# GD32W515Px register map
File version: 1.0
CPU: CM33 r0p0, little endian, MPU, FPU, 4 interrupt priority bits
Registers are 32-bit, read-write, reset 0x0 unless marked. A register's access mark holds for its fields unless they carry their own. Offsets are from the block's base; [hi:lo] are bit positions; {n}, {i} and the like mark numbered series.

## SYSCFG — System configuration controller
Base 0x40013800
Same registers: SEC_SYSCFG 0x50013800
0x00 CFG0 — Configuration register 0
  [1:0] BOOT_MODE
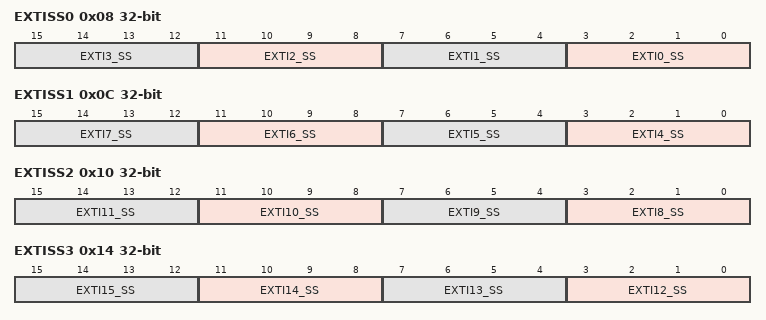
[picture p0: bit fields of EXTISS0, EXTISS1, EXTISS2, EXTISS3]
0x08 EXTISS0 — EXTI sources selection register 0
  [4n+3:4n] EXTI{n}_SS (n=0..3) — EXTI {n} sources selection
0x0C EXTISS1 — EXTI sources selection register 1
  [4n-13:4n-16] EXTI{n}_SS (n=4..7) — EXTI {n} sources selection
0x10 EXTISS2 — EXTI sources selection register 2
  [4n-29:4n-32] EXTI{n}_SS (n=8..11) — EXTI {n} sources selection
0x14 EXTISS3 — EXTI sources selection register 3
  [4n-45:4n-48] EXTI{n}_SS (n=12..15) — EXTI {n} sources selection
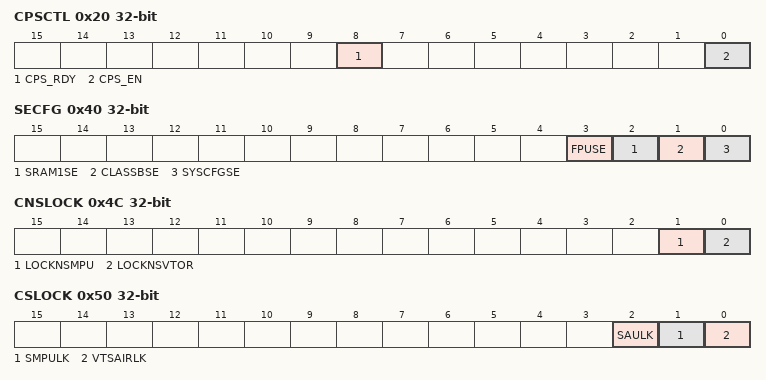
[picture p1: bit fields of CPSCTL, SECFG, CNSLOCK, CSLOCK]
0x20 CPSCTL access per field — I/O compensation control register
  [8] CPS_RDY ro — I/O compensation cell is ready or not
  [0] CPS_EN rw — I/O compensation cell enable
0x40 SECFG — SYSCFG secure configuration register
  [3] FPUSE — FPU security
  [2] SRAM1SE — SRAM1 security
  [1] CLASSBSE — ClassB security
  [0] SYSCFGSE — SYSCFG clock control security
0x48 FPUINTMSK reset 0x1F — FPU interrupt mask register
  [5:0] FPU_IE — Floating point unit interrupts enable bits
0x4C CNSLOCK — SYSCFG CPU non-secure lock register
  [1] LOCKNSMPU — Non-secure MPU registers lock
  [0] LOCKNSVTOR — VTOR_NS register lock
0x50 CSLOCK — SYSCFG CPU secure lock register
  [2] SAULK — SAU registers lock
  [1] SMPULK — Secure MPU registers lock
  [0] VTSAIRLK — VTOR_S register and AIRCR register bits lock
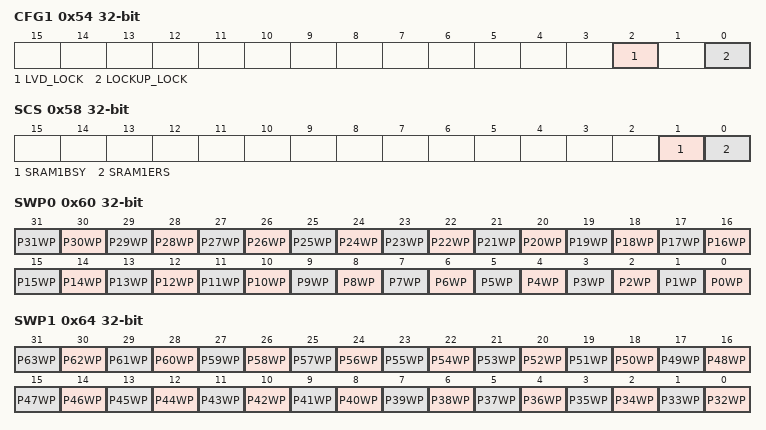
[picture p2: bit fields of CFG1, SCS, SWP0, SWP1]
0x54 CFG1 — SYSCFG configuration register 1
  [2] LVD_LOCK — LVD lock enable bit
  [0] LOCKUP_LOCK — Cortex M33 LOCKUP (hardfault) output enable bit
0x58 SCS access per field — SYSCFG SRAM1 control and status register
  [1] SRAM1BSY ro — SRAM1 busy by erase operation
  [0] SRAM1ERS rw — SRAM1 erase
0x5C SKEY wo — SYSCFG SRAM1 key register
  [7:0] KEY — SRAM1 write protection key for software erase
0x60 SWP0 — SYSCFG SRAM1 write protection register 0
  [n] P{n}WP (n=0..31) — SRAM1 1 Kbyte page {n} write protection
0x64 SWP1 — SYSCFG SRAM1 write protection register 1
  [n-32] P{n}WP (n=32..63) — SRAM1 1 Kbyte page {n} write protection
0x6C RSSCMD — SYSCFG RSS command register
  [7:0] RSSCMD — RSS commands

## TZBMPC0 — Memory protection controller - block based
Base 0x400A0800
Same registers: SEC_TZBMPC0 0x500A0800
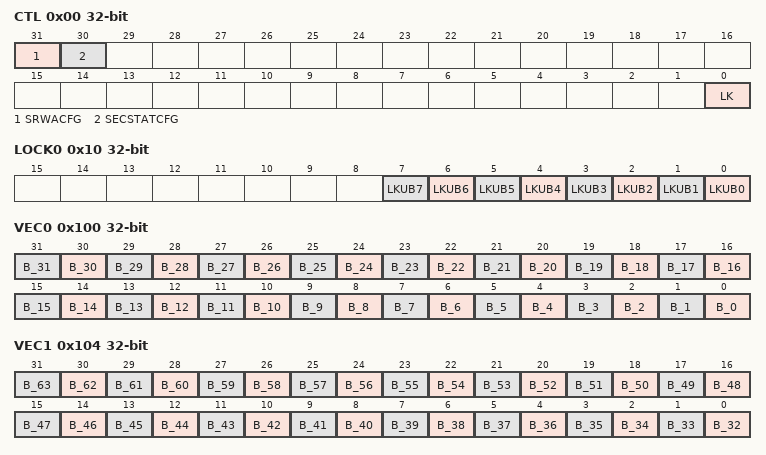
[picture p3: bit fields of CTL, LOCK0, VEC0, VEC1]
0x00 CTL — TZBMPC0 control register
  [31] SRWACFG — secure read/write illegal access disable
  [30] SECSTATCFG — default security state
  [0] LK — TZSPC items lock configuration bit
0x10 LOCK0 — TZBMPC0 lock register 0
  [n] LKUB{n} (n=0..7) — lock/unlock status of secure access mode for the super-blocks {n}
0x100 VEC0 — TZBMPC0 vector register 0
  [n] B_{n} (n=0..31) — blocks {n}
0x104 VEC1 — TZBMPC0 vector register 1
  [n-32] B_{n} (n=32..63) — blocks {n}
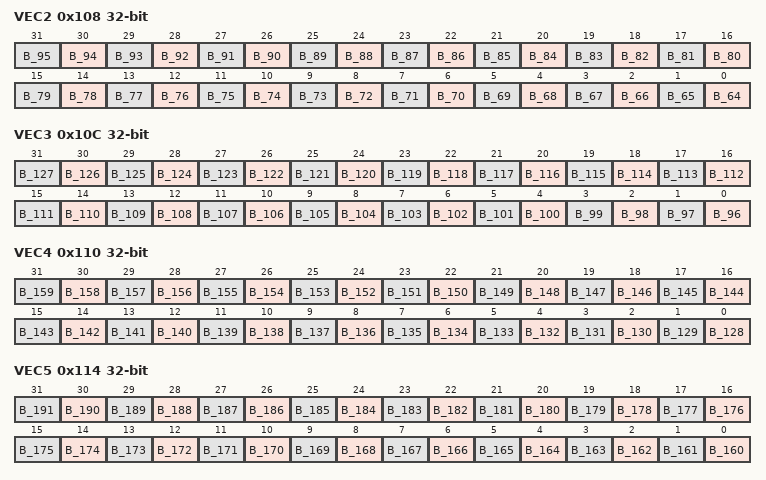
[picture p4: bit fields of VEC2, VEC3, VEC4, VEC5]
0x108 VEC2 — TZBMPC0 vector register 2
  [n-64] B_{n} (n=64..95) — blocks {n}
0x10C VEC3 — TZBMPC0 vector register 3
  [n-96] B_{n} (n=96..127) — blocks {n}
0x110 VEC4 — TZBMPC0 vector register 4
  [n-128] B_{n} (n=128..159) — blocks {n}
0x114 VEC5 — TZBMPC0 vector register 5
  [n-160] B_{n} (n=160..191) — blocks {n}
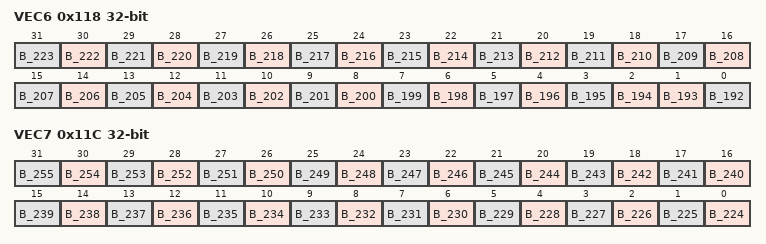
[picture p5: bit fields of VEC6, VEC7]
0x118 VEC6 — TZBMPC0 vector register 6
  [n-192] B_{n} (n=194..223) — blocks {n}
  [1] B_193 — blocks 93
  [0] B_192 — blocks 192
0x11C VEC7 — TZBMPC0 vector register 7
  [n-224] B_{n} (n=224..255) — blocks {n}

## TZBMPC1 — Memory protection controller - block based
Base 0x400A0C00
Same registers: SEC_TZBMPC1 0x500A0C00
Registers as TZBMPC0 (with TZBMPC0 read as TZBMPC1); these are added or differ:
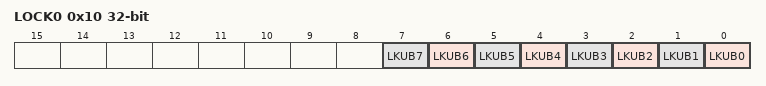
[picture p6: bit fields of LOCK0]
0x10 LOCK0 — TZBMPC1 lock register0
  [n] LKUB{n} (n=0..7) — lock/unlock status of secure access mode for the super-blocks {n}

## WWDGT — Window watchdog timer
Base 0x40002C00
Same registers: SEC_WWDGT 0x50002C00
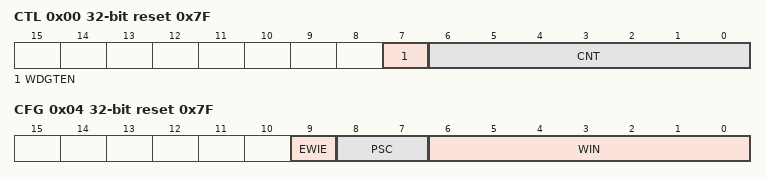
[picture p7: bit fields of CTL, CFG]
0x00 CTL reset 0x7F — Control register
  [7] WDGTEN — Activation bit
  [6:0] CNT — 7-bit counter
0x04 CFG reset 0x7F — Configuration register
  [9] EWIE — Early wakeup interrupt
  [8:7] PSC — Prescaler
  [6:0] WIN — 7-bit window value
0x08 STAT — Status register
  [0] EWIF — Early wakeup interrupt flag
